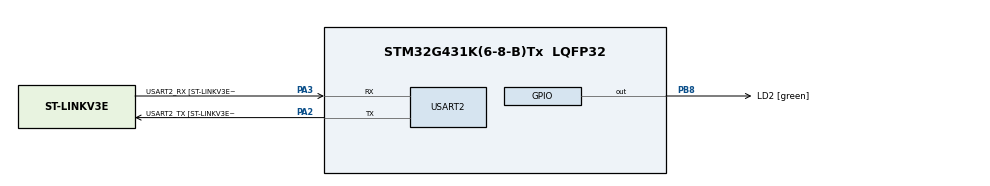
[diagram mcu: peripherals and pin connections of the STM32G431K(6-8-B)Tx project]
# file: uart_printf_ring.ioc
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Mcu.Family=STM32G4
Mcu.Name=STM32G431K(6-8-B)Tx
Mcu.Package=LQFP32
NVIC.PriorityGroup=NVIC_PRIORITYGROUP_4
NVIC.USART2_IRQn=true\:0\:0\:false\:false\:true\:true\:true\:true
PA13.GPIO_Label=T_SWDIO
PA13.Mode=Serial_Wire
PA13.Signal=SYS_JTMS-SWDIO
PA14.GPIO_Label=T_SWCLK
PA14.Mode=Serial_Wire
PA14.Signal=SYS_JTCK-SWCLK
PA2.GPIO_Label=USART2_TX [ST-LINKV3E_VCP_RX]
PA2.Mode=Asynchronous
PA2.Signal=USART2_TX
PA3.GPIO_Label=USART2_RX [ST-LINKV3E_VCP_TX]
PA3.Mode=Asynchronous
PA3.Signal=USART2_RX
PB3.GPIO_Label=T_SWO
PB3.Signal=SYS_JTDO-SWO
PB8-BOOT0.GPIO_Label=LD2 [green]
PB8-BOOT0.Signal=GPIO_Output
ProjectManager.HeapSize=0x200
ProjectManager.StackSize=0x400
ProjectManager.TargetToolchain=STM32CubeIDE
RCC.ADC12Freq_Value=170000000
RCC.AHBFreq_Value=170000000
RCC.APB1Freq_Value=170000000
RCC.APB1TimFreq_Value=170000000
RCC.APB2Freq_Value=170000000
RCC.APB2TimFreq_Value=170000000
RCC.CortexFreq_Value=170000000
RCC.EXTERNAL_CLOCK_VALUE=12288000
RCC.HCLKFreq_Value=170000000
RCC.HSE_VALUE=8000000
RCC.HSI48_VALUE=48000000
RCC.HSI_VALUE=16000000
RCC.LSE_VALUE=32768
RCC.PLLM=RCC_PLLM_DIV4
RCC.PLLN=85
RCC.SYSCLKFreq_VALUE=170000000
RCC.SYSCLKSource=RCC_SYSCLKSOURCE_PLLCLK
RCC.USBFreq_Value=170000000
RCC.VCOOutputFreq_Value=340000000
USART2.BaudRate=(MY_UART_BAUDRATE)
USART2.VirtualMode-Asynchronous=VM_ASYNC
USART2.WordLength=WORDLENGTH_8B
board=NUCLEO-G431KB

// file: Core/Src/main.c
/* USER CODE BEGIN Header */
/**
  ******************************************************************************
  * @file           : main.c
  * @brief          : Main program body
  ******************************************************************************
  * @attention
  *
  * Copyright (c) 2024 STMicroelectronics.
  * All rights reserved.
  *
  * This software is licensed under terms that can be found in the LICENSE file
  * in the root directory of this software component.
  * If no LICENSE file comes with this software, it is provided AS-IS.
  *
  ******************************************************************************
  */
/* USER CODE END Header */
#include "main.h"

/* USER CODE BEGIN Includes */
#include "../../User/user_main.h"
/* USER CODE END Includes */

void SystemClock_Config(void);
static void MX_GPIO_Init(void);
static void MX_USART2_UART_Init(void);

int main(void)
{

  /* MCU Configuration--------------------------------------------------------*/

  /* Reset of all peripherals, Initializes the Flash interface and the Systick. */
  LL_APB2_GRP1_EnableClock(LL_APB2_GRP1_PERIPH_SYSCFG);
  LL_APB1_GRP1_EnableClock(LL_APB1_GRP1_PERIPH_PWR);

  /* System interrupt init*/
  NVIC_SetPriorityGrouping(NVIC_PRIORITYGROUP_4);

  /* Configure the system clock */
  SystemClock_Config();

  /* Initialize all configured peripherals */
  MX_GPIO_Init();
  MX_USART2_UART_Init();
  /* USER CODE BEGIN 2 */
  user_init();
  /* USER CODE END 2 */

  /* Infinite loop */
  /* USER CODE BEGIN WHILE */
  while (1)
  {
	user_loop();
    /* USER CODE END WHILE */

  }
}

void SystemClock_Config(void)
{
  LL_FLASH_SetLatency(LL_FLASH_LATENCY_4);
  while(LL_FLASH_GetLatency() != LL_FLASH_LATENCY_4)
  {
  }
  LL_PWR_EnableRange1BoostMode();
  LL_RCC_HSI_Enable();
   /* Wait till HSI is ready */
  while(LL_RCC_HSI_IsReady() != 1)
  {
  }

  LL_RCC_HSI_SetCalibTrimming(64);
  LL_RCC_PLL_ConfigDomain_SYS(LL_RCC_PLLSOURCE_HSI, LL_RCC_PLLM_DIV_4, 85, LL_RCC_PLLR_DIV_2);
  LL_RCC_PLL_EnableDomain_SYS();
  LL_RCC_PLL_Enable();
   /* Wait till PLL is ready */
  while(LL_RCC_PLL_IsReady() != 1)
  {
  }

  LL_RCC_SetSysClkSource(LL_RCC_SYS_CLKSOURCE_PLL);
  LL_RCC_SetAHBPrescaler(LL_RCC_SYSCLK_DIV_2);
   /* Wait till System clock is ready */
  while(LL_RCC_GetSysClkSource() != LL_RCC_SYS_CLKSOURCE_STATUS_PLL)
  {
  }

  /* Insure 1us transition state at intermediate medium speed clock*/
  for (__IO uint32_t i = (170 >> 1); i !=0; i--);

  /* Set AHB prescaler*/
  LL_RCC_SetAHBPrescaler(LL_RCC_SYSCLK_DIV_1);
  LL_RCC_SetAPB1Prescaler(LL_RCC_APB1_DIV_1);
  LL_RCC_SetAPB2Prescaler(LL_RCC_APB2_DIV_1);

  LL_Init1msTick(170000000);

  LL_SetSystemCoreClock(170000000);
}

static void MX_USART2_UART_Init(void)
{

  LL_USART_InitTypeDef USART_InitStruct = {0};

  LL_GPIO_InitTypeDef GPIO_InitStruct = {0};

  LL_RCC_SetUSARTClockSource(LL_RCC_USART2_CLKSOURCE_PCLK1);

  /* Peripheral clock enable */
  LL_APB1_GRP1_EnableClock(LL_APB1_GRP1_PERIPH_USART2);

  LL_AHB2_GRP1_EnableClock(LL_AHB2_GRP1_PERIPH_GPIOA);
  /**USART2 GPIO Configuration
  PA2   ------> USART2_TX
  PA3   ------> USART2_RX
  */
  GPIO_InitStruct.Pin = USART2_TX_Pin;
  GPIO_InitStruct.Mode = LL_GPIO_MODE_ALTERNATE;
  GPIO_InitStruct.Speed = LL_GPIO_SPEED_FREQ_LOW;
  GPIO_InitStruct.OutputType = LL_GPIO_OUTPUT_PUSHPULL;
  GPIO_InitStruct.Pull = LL_GPIO_PULL_NO;
  GPIO_InitStruct.Alternate = LL_GPIO_AF_7;
  LL_GPIO_Init(USART2_TX_GPIO_Port, &GPIO_InitStruct);

  GPIO_InitStruct.Pin = USART2_RX_Pin;
  GPIO_InitStruct.Mode = LL_GPIO_MODE_ALTERNATE;
  GPIO_InitStruct.Speed = LL_GPIO_SPEED_FREQ_LOW;
  GPIO_InitStruct.OutputType = LL_GPIO_OUTPUT_PUSHPULL;
  GPIO_InitStruct.Pull = LL_GPIO_PULL_NO;
  GPIO_InitStruct.Alternate = LL_GPIO_AF_7;
  LL_GPIO_Init(USART2_RX_GPIO_Port, &GPIO_InitStruct);

  /* USART2 interrupt Init */
  NVIC_SetPriority(USART2_IRQn, NVIC_EncodePriority(NVIC_GetPriorityGrouping(),0, 0));
  NVIC_EnableIRQ(USART2_IRQn);

  USART_InitStruct.PrescalerValue = LL_USART_PRESCALER_DIV1;
  USART_InitStruct.BaudRate = (MY_UART_BAUDRATE);
  USART_InitStruct.DataWidth = LL_USART_DATAWIDTH_8B;
  USART_InitStruct.StopBits = LL_USART_STOPBITS_1;
  USART_InitStruct.Parity = LL_USART_PARITY_NONE;
  USART_InitStruct.TransferDirection = LL_USART_DIRECTION_TX_RX;
  USART_InitStruct.HardwareFlowControl = LL_USART_HWCONTROL_NONE;
  USART_InitStruct.OverSampling = LL_USART_OVERSAMPLING_16;
  LL_USART_Init(USART2, &USART_InitStruct);
  LL_USART_SetTXFIFOThreshold(USART2, LL_USART_FIFOTHRESHOLD_1_8);
  LL_USART_SetRXFIFOThreshold(USART2, LL_USART_FIFOTHRESHOLD_1_8);
  LL_USART_DisableFIFO(USART2);
  LL_USART_ConfigAsyncMode(USART2);

  LL_USART_Enable(USART2);

  /* Polling USART2 initialisation */
  while((!(LL_USART_IsActiveFlag_TEACK(USART2))) || (!(LL_USART_IsActiveFlag_REACK(USART2))))
  {
  }

}

static void MX_GPIO_Init(void)
{
  LL_GPIO_InitTypeDef GPIO_InitStruct = {0};

  /* GPIO Ports Clock Enable */
  LL_AHB2_GRP1_EnableClock(LL_AHB2_GRP1_PERIPH_GPIOA);
  LL_AHB2_GRP1_EnableClock(LL_AHB2_GRP1_PERIPH_GPIOB);

  /**/
  LL_GPIO_ResetOutputPin(LD2_GPIO_Port, LD2_Pin);

  /**/
  GPIO_InitStruct.Pin = LD2_Pin;
  GPIO_InitStruct.Mode = LL_GPIO_MODE_OUTPUT;
  GPIO_InitStruct.Speed = LL_GPIO_SPEED_FREQ_LOW;
  GPIO_InitStruct.OutputType = LL_GPIO_OUTPUT_PUSHPULL;
  GPIO_InitStruct.Pull = LL_GPIO_PULL_NO;
  LL_GPIO_Init(LD2_GPIO_Port, &GPIO_InitStruct);

}

void Error_Handler(void)
{
  __disable_irq();
  while (1)
  {
  }
}
